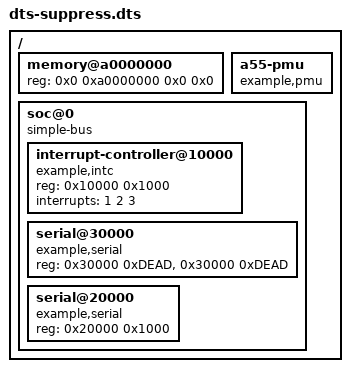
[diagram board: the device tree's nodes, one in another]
// SPDX-License-Identifier: GPL-2.0-only OR BSD-2-Clause
/dts-v1/;

/ {
	#address-cells = <1>;
	#size-cells = <1>;

	memory@a0000000 {
		device_type = "memory";
		reg = <0x0 0xa0000000 0x0 0x0>;
	};

	/* Wrong rule suppressed */
	/* dt-check-style disable=child-address-order */
	a55-pmu {
		compatible = "example,pmu";
	};

	soc@0 {
		compatible = "simple-bus";
		ranges = <0 0 0 0xc0000000>;

		#address-cells = <1>;
		#size-cells = <1>;

		/* Should not affect the node after this one */
		/* dt-check-style disable=hex-case */
		interrupt-controller@10000 {
			compatible = "example,intc";
			reg = <0x10000 0x1000>;
			/* Wrong rule suppressed */
			/* dt-check-style disable=continuation-alignment */
			interrupts =  <1 2 3>;
		};

		serial@30000 {
			compatible = "example,serial";
			/* dt-check-style disable=continuation-alignment */
			reg =  <0x30000 0xDEAD>,
				<0x30000 0xDEAD>;
			/* Ignored suppression not followed by node open or property */
			/* dt-check-style disable=child-address-order */
		};

		/* Wrong rule suppressed */
		/* dt-check-style disable=child-name-order */
		serial@20000 {
			compatible  = "example,serial";
			reg = <0x20000 0x1000>;
		};
	};
};
